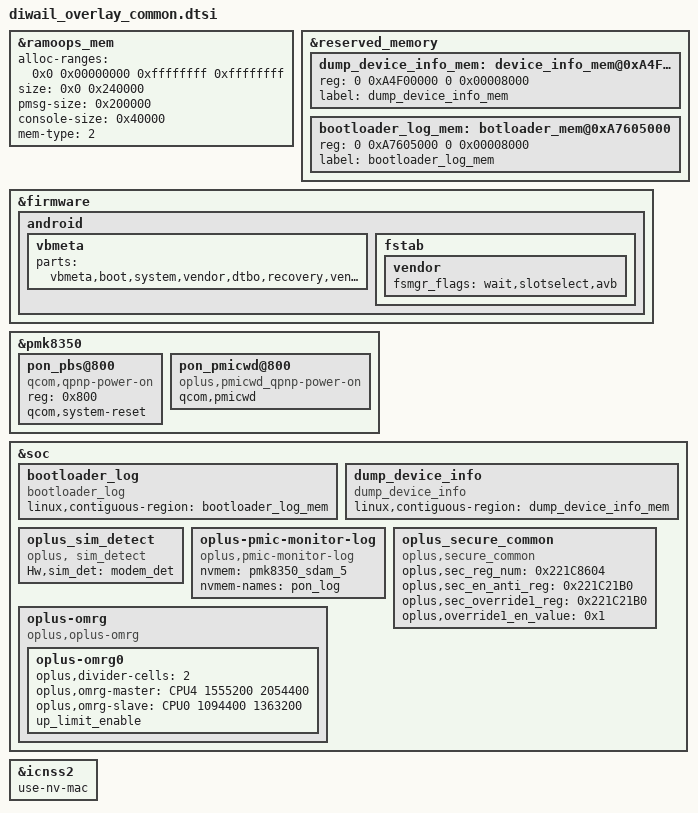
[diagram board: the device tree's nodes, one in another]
&ramoops_mem {
	alloc-ranges = <0x0 0x00000000 0xffffffff 0xffffffff>;
	size = <0x0 0x240000>;
	pmsg-size = <0x200000>;
	console-size = <0x40000>;
	mem-type = <2>;
};

&reserved_memory {
	/* #ifdef OPLUS_FEATURE_DUMP_DEVICE_INFO */
	dump_device_info_mem: device_info_mem@0xA4F00000 {
		reg = <0 0xA4F00000 0 0x00008000>;
		label = "dump_device_info_mem";
	};
	/* #endif OPLUS_FEATURE_DUMP_DEVICE_INFO */
	/*
	uefiplat.cfg
	0xA7605000, 0x00008000, "Log Buffer",        AddMem, SYS_MEM, SYS_MEM_CAP, RtData, WRITE_BACK_XN
	*/
	bootloader_log_mem: botloader_mem@0xA7605000 {
		reg = <0 0xA7605000 0 0x00008000>;
		label = "bootloader_log_mem";
	};
};

&firmware {
		android {
			vbmeta {
				//#ifndef OPLUS_FEATURE_SECURITY_COMMON
				/*2021/09/26 Add verify boot*/
				parts = "vbmeta,boot,system,vendor,dtbo,recovery,vendor_boot";
				//#else
				//parts = "vbmeta,boot,system,vendor,dtbo,recovery";
				//#endif /* OPLUS_FEATURE_SECURITY_COMMON */
			};

			fstab {
				vendor {
//#ifndef OPLUS_FEATURE_SECURITY_COMMON
					fsmgr_flags = "wait,slotselect,avb";
//#else
					//fsmgr_flags = "wait,avb";
//#endif /* OPLUS_FEATURE_SECURITY_COMMON */
				};
			};
		};
};

&pmk8350 {
//#ifdef CONFIG_OPLUS_FEATURE_QCOM_PMICWD
//pmicwd depend on pon_pbs@800
		pon_pbs@800 {
			compatible = "qcom,qpnp-power-on";
			reg = <0x800>;
			qcom,system-reset;
		};

		pon_pmicwd@800 {
		compatible = "oplus,pmicwd_qpnp-power-on";
		qcom,pmicwd;
	};
//#endif /* CONFIG_OPLUS_FEATURE_QCOM_PMICWD */
};

&soc {
	bootloader_log {
		compatible = "bootloader_log";
		linux,contiguous-region = <&bootloader_log_mem>;
	};
	/* #ifdef OPLUS_FEATURE_DUMP_DEVICE_INFO */
	dump_device_info {
		compatible = "dump_device_info";
		linux,contiguous-region = <&dump_device_info_mem>;
	};
	/* #endif OPLUS_FEATURE_DUMP_DEVICE_INFO */

	//#ifdef OPLUS_FEATRUE_SIM_HOLDER_DETECT
	oplus_sim_detect {
		compatible = "oplus, sim_detect";
		Hw,sim_det = "modem_det";
	};

	//#endif /* OPLUS_FEATRUE_SIM_HOLDER_DETECT */

	//#ifdef CONFIG_OPLUS_FEATURE_PMIC_MONITOR, read pmic info from nvmem(only for xblloader close)
		oplus-pmic-monitor-log {
			compatible = "oplus,pmic-monitor-log";
			nvmem = <&pmk8350_sdam_5>;
			nvmem-names = "pon_log";
		};
	//#endif

	//#endif /* OPLUS_FEATRUE_SIM_HOLDER_DETECT */

	//#ifdef OPLUS_FEATURE_SECURITY_COMMON
	/* 2022/02/19 add for oplus secure */
	oplus_secure_common {
		compatible = "oplus,secure_common";
		oplus,sec_reg_num = <0x221C8604>;
		oplus,sec_en_anti_reg = <0x221C21B0>;
		oplus,sec_override1_reg = <0x221C21B0>;
		oplus,override1_en_value = <0x1>;
	};
	//#endif /*OPLUS_FEATURE_SECURITY_COMMON*/

	//#ifdef CONFIG_OPLUS_OMRG
	oplus-omrg {
		compatible = "oplus,oplus-omrg";
		oplus-omrg0 {
			oplus,divider-cells = <2>;
			oplus,omrg-master = <&CPU4 1555200 2054400>;
			oplus,omrg-slave = <&CPU0 1094400 1363200>;
			up_limit_enable;
			/* down_limit_enable; */
			/* thermal_enable; */
		};
	};
	//#endif /* CONFIG_OPLUS_OMRG */
};

//#ifdef OPLUS_FEATURE_WIFI_MAC
&icnss2 {
	use-nv-mac;
};
//#endif /* OPLUS_FEATURE_WIFI_MAC */
